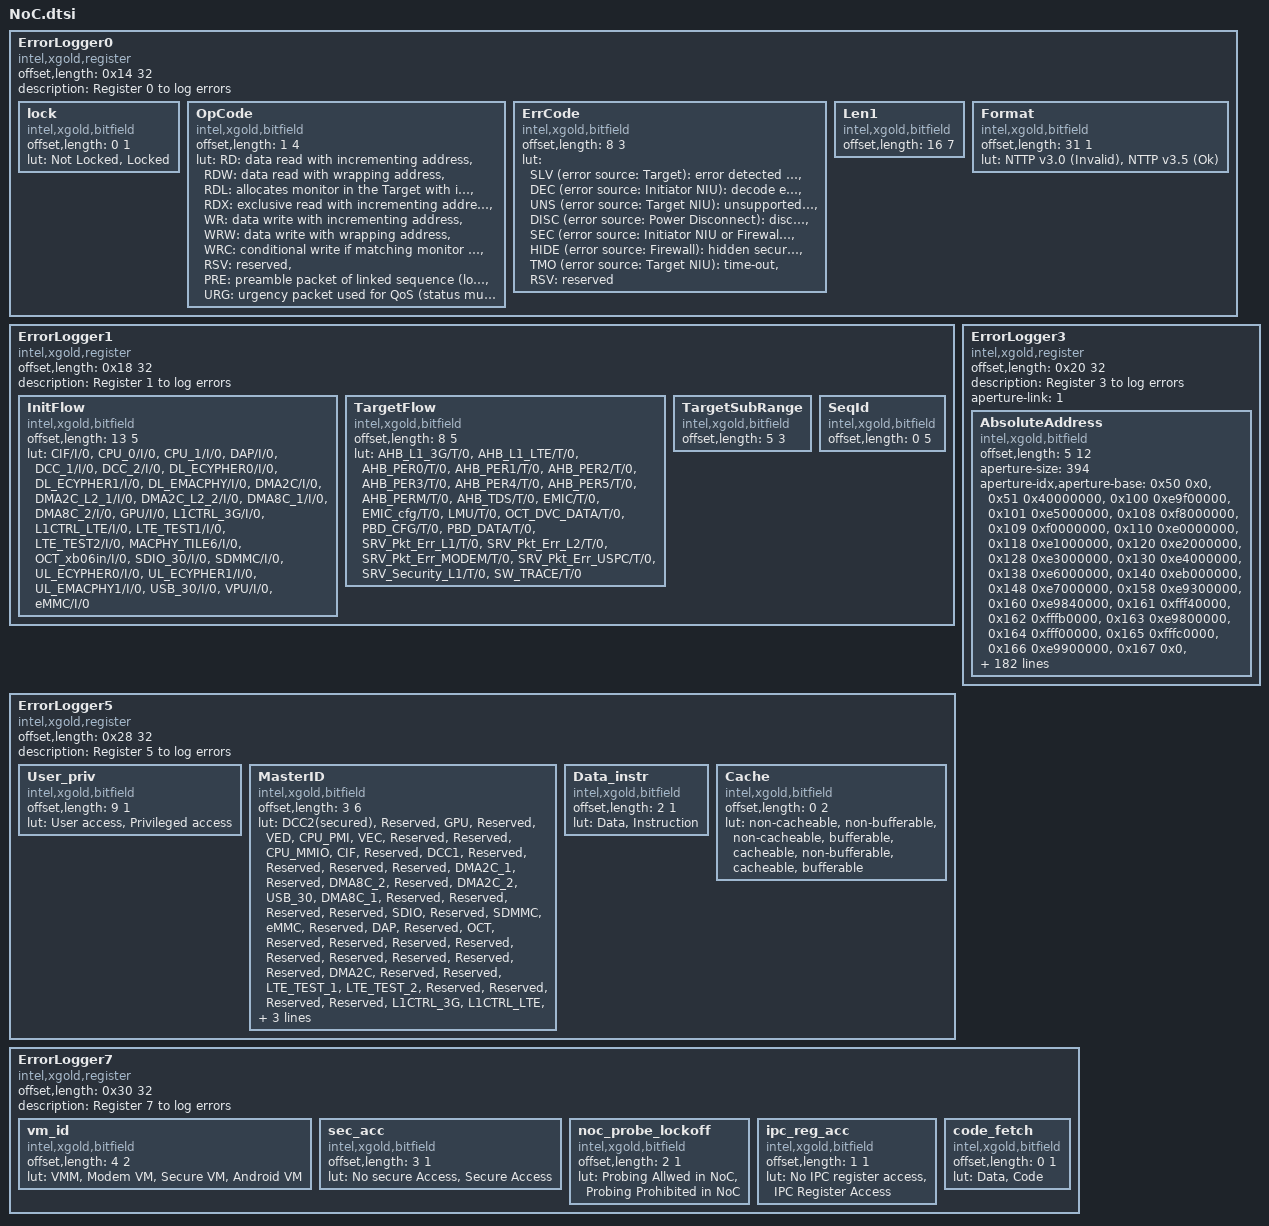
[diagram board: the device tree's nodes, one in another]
ErrorLogger0 {
	compatible = "intel,xgold,register";
	offset,length = < 0x14 32>;
	description = "Register 0 to log errors";
	lock {
		compatible = "intel,xgold,bitfield";
		offset,length = < 0 1>;
		lut = "Not Locked", "Locked";
	};
	OpCode {
		compatible = "intel,xgold,bitfield";
		offset,length = < 1 4>;
		lut = "RD: data read with incrementing address",
			"RDW: data read with wrapping address",
			"RDL: allocates monitor in the Target with incrementing address",
			"RDX: exclusive read with incrementing address",
			"WR: data write with incrementing address",
			"WRW: data write with wrapping address",
			"WRC: conditional write if matching monitor in Target is found",
			"RSV: reserved",
			"PRE: preamble packet of linked sequence (locked sequence)",
			"URG: urgency packet used for QoS (status must be REQ)";
	};
	ErrCode {
		compatible = "intel,xgold,bitfield";
		offset,length = < 8 3 >;
		lut = "SLV (error source: Target): error detected by the Slave without any information or no Error",
			"DEC (error source: Initiator NIU): decode error",
			"UNS (error source: Target NIU): unsupported access type",
			"DISC (error source: Power Disconnect): disconnected Target or NoC domain",
			"SEC (error source: Initiator NIU or Firewall): security error",
			"HIDE (error source: Firewall): hidden security error. Will be reported as OK to the initiator",
			"TMO (error source: Target NIU): time-out",
			"RSV: reserved";

	};
	Len1 {
		compatible = "intel,xgold,bitfield";
		offset,length = < 16 7 >;
	};
	Format {
		compatible = "intel,xgold,bitfield";
		offset,length = < 31 1 >;
		lut = "NTTP v3.0 (Invalid)", "NTTP v3.5 (Ok)";
	};
};

ErrorLogger1 {
	compatible = "intel,xgold,register", "intel,xgold,noc,filter,routeid";
	offset,length = < 0x18 32>;
	description = "Register 1 to log errors";
	InitFlow {
		compatible = "intel,xgold,bitfield";
		offset,length = < 13 5 >;
		lut = "CIF/I/0",
			"CPU_0/I/0",
			"CPU_1/I/0",
			"DAP/I/0",
			"DCC_1/I/0",
			"DCC_2/I/0",
			"DL_ECYPHER0/I/0",
			"DL_ECYPHER1/I/0",
			"DL_EMACPHY/I/0",
			"DMA2C/I/0",
			"DMA2C_L2_1/I/0",
			"DMA2C_L2_2/I/0",
			"DMA8C_1/I/0",
			"DMA8C_2/I/0",
			"GPU/I/0",
			"L1CTRL_3G/I/0",
			"L1CTRL_LTE/I/0",
			"LTE_TEST1/I/0",
			"LTE_TEST2/I/0",
			"MACPHY_TILE6/I/0",
			"OCT_xb06in/I/0",
			"SDIO_30/I/0",
			"SDMMC/I/0",
			"UL_ECYPHER0/I/0",
			"UL_ECYPHER1/I/0",
			"UL_EMACPHY1/I/0",
			"USB_30/I/0",
			"VPU/I/0",
			"eMMC/I/0";
	};

	TargetFlow {
		compatible = "intel,xgold,bitfield";
		offset,length = < 8 5 >;
		lut =   "AHB_L1_3G/T/0",
			"AHB_L1_LTE/T/0",
			"AHB_PER0/T/0",
			"AHB_PER1/T/0",
			"AHB_PER2/T/0",
			"AHB_PER3/T/0",
			"AHB_PER4/T/0",
			"AHB_PER5/T/0",
			"AHB_PERM/T/0",
			"AHB_TDS/T/0",
			"EMIC/T/0",
			"EMIC_cfg/T/0",
			"LMU/T/0",
			"OCT_DVC_DATA/T/0",
			"PBD_CFG/T/0",
			"PBD_DATA/T/0",
			"SRV_Pkt_Err_L1/T/0",
			"SRV_Pkt_Err_L2/T/0",
			"SRV_Pkt_Err_MODEM/T/0",
			"SRV_Pkt_Err_USPC/T/0",
			"SRV_Security_L1/T/0",
			"SW_TRACE/T/0";
	};

	TargetSubRange {
		compatible = "intel,xgold,bitfield";
		offset,length = < 5 3 >;
	};

	SeqId {
		compatible = "intel,xgold,bitfield";
		offset,length = < 0 5 >;
	};
};

ErrorLogger3 {
	/* This register does not really include a bitfield or its bitfield is 32 bits and it provides an offset address */
	/* To calculate the absolute address, you must use the initflow:targetflow:subrange from ErrorLogger3 register */
	/* And use it as an index in the aperture table. Then you must add the value of this register to the value given */
	/* by the table to get the absolute address. */
	compatible = "intel,xgold,register";
	offset,length = < 0x20 32>;
	description = "Register 3 to log errors";
	aperture-link = <1>; /* link to ErrorLogger1 whose information are required to calculate real absolute address */
	AbsoluteAddress {
		compatible = "intel,xgold,bitfield";
		offset,length = < 5 12 >;				/* bitfield initflow:targeflow:subrange from aperture-link register */
		aperture-size= < 394 >;					/* Number of line in the aperture table below */
		aperture-idx,aperture-base =			/* Aperture_idx is concatenation of initflow:targetflow:subrange bitfield from ErrorLogger1 */
    <0x50  0x0>,
    <0x51  0x40000000>,
    <0x100 0xe9f00000>,
    <0x101 0xe5000000>,
    <0x108 0xf8000000>,
    <0x109 0xf0000000>,
    <0x110 0xe0000000>,
    <0x118 0xe1000000>,
    <0x120 0xe2000000>,
    <0x128 0xe3000000>,
    <0x130 0xe4000000>,
    <0x138 0xe6000000>,
    <0x140 0xeb000000>,
    <0x148 0xe7000000>,
    <0x158 0xe9300000>,
    <0x160 0xe9840000>,
    <0x161 0xfff40000>,
    <0x162 0xfffb0000>,
    <0x163 0xe9800000>,
    <0x164 0xfff00000>,
    <0x165 0xfffc0000>,
    <0x166 0xe9900000>,
    <0x167 0x0>,
    <0x170 0xe9400000>,
    <0x178 0xe9480000>,
    <0x180 0xe9010000>,
    <0x181 0xe9013600>,
    <0x182 0xe9013400>,
    <0x183 0xe9013000>,
    <0x184 0xe9012000>,
    <0x188 0xe9014000>,
    <0x189 0xe9017400>,
    <0x18a 0xe9017000>,
    <0x18b 0xe9016000>,
    <0x190 0xe9018000>,
    <0x191 0xe901ac00>,
    <0x192 0xe901a800>,
    <0x193 0xe901a000>,
    <0x198 0xe901c000>,
    <0x199 0xe901e400>,
    <0x19a 0xe901e000>,
    <0x1a0 0xe9000000>,
    <0x1a1 0xe9002000>,
    <0x1a8 0x80000000>,
    <0x250 0x0>,
    <0x251 0x40000000>,
    <0x260 0xe9840000>,
    <0x261 0xfff40000>,
    <0x262 0xfffb0000>,
    <0x263 0xe9800000>,
    <0x264 0xfff00000>,
    <0x265 0xfffc0000>,
    <0x266 0xe9900000>,
    <0x267 0x0>,
    <0x300 0xe9f00000>,
    <0x301 0xe5000000>,
    <0x308 0xf8000000>,
    <0x309 0xf0000000>,
    <0x310 0xe0000000>,
    <0x318 0xe1000000>,
    <0x320 0xe2000000>,
    <0x328 0xe3000000>,
    <0x330 0xe4000000>,
    <0x338 0xe6000000>,
    <0x340 0xeb000000>,
    <0x348 0xe7000000>,
    <0x350 0x0>,
    <0x351 0x40000000>,
    <0x358 0xe9300000>,
    <0x360 0xe9840000>,
    <0x361 0xfff40000>,
    <0x362 0xfffb0000>,
    <0x363 0xe9800000>,
    <0x364 0xfff00000>,
    <0x365 0xfffc0000>,
    <0x366 0xe9900000>,
    <0x370 0xe9400000>,
    <0x378 0xe9480000>,
    <0x380 0xe9010000>,
    <0x381 0xe9013600>,
    <0x382 0xe9013400>,
    <0x383 0xe9013000>,
    <0x384 0xe9012000>,
    <0x388 0xe9014000>,
    <0x389 0xe9017400>,
    <0x38a 0xe9017000>,
    <0x38b 0xe9016000>,
    <0x390 0xe9018000>,
    <0x391 0xe901ac00>,
    <0x392 0xe901a800>,
    <0x393 0xe901a000>,
    <0x398 0xe901c000>,
    <0x399 0xe901e400>,
    <0x39a 0xe901e000>,
    <0x39b 0x0>,
    <0x3a0 0xe9000000>,
    <0x3a1 0xe9002000>,
    <0x450 0x0>,
    <0x451 0x40000000>,
    <0x452 0x0>,
    <0x550 0x0>,
    <0x551 0x40000000>,
    <0x552 0x0>,
    <0x600 0xe9f00000>,
    <0x601 0xe5000000>,
    <0x608 0xf8000000>,
    <0x609 0xf0000000>,
    <0x650 0x0>,
    <0x651 0x40000000>,
    <0x660 0xe9840000>,
    <0x661 0xfff40000>,
    <0x662 0xfffb0000>,
    <0x663 0xe9800000>,
    <0x664 0xfff00000>,
    <0x665 0xfffc0000>,
    <0x666 0xe9900000>,
    <0x670 0xe9400000>,
    <0x671 0x0>,
    <0x678 0xe9480000>,
    <0x700 0xe9f00000>,
    <0x701 0xe5000000>,
    <0x708 0xf8000000>,
    <0x709 0xf0000000>,
    <0x750 0x0>,
    <0x751 0x40000000>,
    <0x760 0xe9840000>,
    <0x761 0xfff40000>,
    <0x762 0xfffb0000>,
    <0x763 0xe9800000>,
    <0x764 0xfff00000>,
    <0x765 0xfffc0000>,
    <0x766 0xe9900000>,
    <0x770 0xe9400000>,
    <0x771 0x0>,
    <0x778 0xe9480000>,
    <0x800 0xe9f00000>,
    <0x801 0xe5000000>,
    <0x808 0xf8000000>,
    <0x809 0xf0000000>,
    <0x850 0x0>,
    <0x851 0x40000000>,
    <0x860 0xe9840000>,
    <0x861 0xfff40000>,
    <0x862 0xfffb0000>,
    <0x863 0xe9800000>,
    <0x864 0xfff00000>,
    <0x865 0xfffc0000>,
    <0x866 0xe9900000>,
    <0x870 0xe9400000>,
    <0x871 0x0>,
    <0x878 0xe9480000>,
    <0x918 0xe1000000>,
    <0x928 0xe3000000>,
    <0x938 0xe6000000>,
    <0x939 0x0>,
    <0x950 0x0>,
    <0x951 0x40000000>,
    <0x960 0xe9840000>,
    <0x961 0xfff40000>,
    <0x962 0xfffb0000>,
    <0x963 0xe9800000>,
    <0x964 0xfff00000>,
    <0x965 0xfffc0000>,
    <0x966 0xe9900000>,
    <0xa50 0x0>,
    <0xa51 0x40000000>,
    <0xa60 0xe9840000>,
    <0xa61 0xfff40000>,
    <0xa62 0xfffb0000>,
    <0xa63 0xe9800000>,
    <0xa64 0xfff00000>,
    <0xa65 0xfffc0000>,
    <0xa66 0xe9900000>,
    <0xa67 0x0>,
    <0xa78 0xe9480000>,
    <0xb50 0x0>,
    <0xb51 0x40000000>,
    <0xb60 0xe9840000>,
    <0xb61 0xfff40000>,
    <0xb62 0xfffb0000>,
    <0xb63 0xe9800000>,
    <0xb64 0xfff00000>,
    <0xb65 0xfffc0000>,
    <0xb66 0xe9900000>,
    <0xb67 0x0>,
    <0xb78 0xe9480000>,
    <0xc00 0xe9f00000>,
    <0xc01 0xe5000000>,
    <0xc08 0xf8000000>,
    <0xc09 0xf0000000>,
    <0xc18 0xe1000000>,
    <0xc20 0xe2000000>,
    <0xc28 0xe3000000>,
    <0xc38 0xe6000000>,
    <0xc40 0xeb000000>,
    <0xc50 0x0>,
    <0xc51 0x40000000>,
    <0xc60 0xe9840000>,
    <0xc61 0xfff40000>,
    <0xc62 0xfffb0000>,
    <0xc63 0xe9800000>,
    <0xc64 0xfff00000>,
    <0xc65 0xfffc0000>,
    <0xc66 0xe9900000>,
    <0xc67 0x0>,
    <0xd00 0xe9f00000>,
    <0xd01 0xe5000000>,
    <0xd08 0xf8000000>,
    <0xd09 0xf0000000>,
    <0xd18 0xe1000000>,
    <0xd20 0xe2000000>,
    <0xd28 0xe3000000>,
    <0xd38 0xe6000000>,
    <0xd40 0xeb000000>,
    <0xd50 0x0>,
    <0xd51 0x40000000>,
    <0xd60 0xe9840000>,
    <0xd61 0xfff40000>,
    <0xd62 0xfffb0000>,
    <0xd63 0xe9800000>,
    <0xd64 0xfff00000>,
    <0xd65 0xfffc0000>,
    <0xd66 0xe9900000>,
    <0xd67 0x0>,
    <0xe50 0x0>,
    <0xe51 0x40000000>,
    <0xe52 0x0>,
    <0xf00 0xe9f00000>,
    <0xf01 0xe5000000>,
    <0xf60 0xe9840000>,
    <0xf61 0xfff40000>,
    <0xf62 0xfffb0000>,
    <0xf63 0xe9800000>,
    <0xf64 0xfff00000>,
    <0xf65 0xfffc0000>,
    <0xf66 0xe9900000>,
    <0xf70 0xe9400000>,
    <0xf71 0x0>,
    <0xf78 0xe9480000>,
    <0x100 0xe9f00000>,
    <0x100 0xe5000000>,
    <0x103 0xe4000000>,
    <0x106 0xe9840000>,
    <0x106 0xfff40000>,
    <0x106 0xfffb0000>,
    <0x106 0xe9800000>,
    <0x106 0xfff00000>,
    <0x106 0xfffc0000>,
    <0x106 0xe9900000>,
    <0x107 0xe9400000>,
    <0x107 0x0>,
    <0x107 0xe9480000>,
    <0x115 0x0>,
    <0x115 0x40000000>,
    <0x116 0xe9840000>,
    <0x116 0xfff40000>,
    <0x116 0xfffb0000>,
    <0x116 0xe9800000>,
    <0x116 0xfff00000>,
    <0x116 0xfffc0000>,
    <0x116 0xe9900000>,
    <0x117 0xe9480000>,
    <0x117 0x0>,
    <0x125 0x0>,
    <0x125 0x40000000>,
    <0x126 0xe9840000>,
    <0x126 0xfff40000>,
    <0x126 0xfffb0000>,
    <0x126 0xe9800000>,
    <0x126 0xfff00000>,
    <0x126 0xfffc0000>,
    <0x126 0xe9900000>,
    <0x127 0xe9480000>,
    <0x127 0x0>,
    <0x130 0xe9f00000>,
    <0x130 0xe5000000>,
    <0x130 0xf8000000>,
    <0x130 0xf0000000>,
    <0x135 0x0>,
    <0x135 0x40000000>,
    <0x136 0xe9840000>,
    <0x136 0xfff40000>,
    <0x136 0xfffb0000>,
    <0x136 0xe9800000>,
    <0x136 0xfff00000>,
    <0x136 0xfffc0000>,
    <0x136 0xe9900000>,
    <0x137 0xe9400000>,
    <0x137 0x0>,
    <0x137 0xe9480000>,
    <0x145 0x0>,
    <0x145 0x40000000>,
    <0x146 0xe9840000>,
    <0x146 0xfff40000>,
    <0x146 0xfffb0000>,
    <0x146 0xe9800000>,
    <0x146 0xfff00000>,
    <0x146 0xfffc0000>,
    <0x146 0xe9900000>,
    <0x146 0x0>,
    <0x155 0x0>,
    <0x155 0x40000000>,
    <0x156 0xe9840000>,
    <0x156 0xfff40000>,
    <0x156 0xfffb0000>,
    <0x156 0xe9800000>,
    <0x156 0xfff00000>,
    <0x156 0xfffc0000>,
    <0x156 0xe9900000>,
    <0x156 0x0>,
    <0x157 0xe9480000>,
    <0x165 0x0>,
    <0x165 0x40000000>,
    <0x166 0xe9840000>,
    <0x166 0xfff40000>,
    <0x166 0xfffb0000>,
    <0x166 0xe9800000>,
    <0x166 0xfff00000>,
    <0x166 0xfffc0000>,
    <0x166 0xe9900000>,
    <0x166 0x0>,
    <0x170 0xe9f00000>,
    <0x170 0xe5000000>,
    <0x170 0xf8000000>,
    <0x170 0xf0000000>,
    <0x175 0x0>,
    <0x175 0x40000000>,
    <0x176 0xe9840000>,
    <0x176 0xfff40000>,
    <0x176 0xfffb0000>,
    <0x176 0xe9800000>,
    <0x176 0xfff00000>,
    <0x176 0xfffc0000>,
    <0x176 0xe9900000>,
    <0x177 0xe9400000>,
    <0x177 0x0>,
    <0x177 0xe9480000>,
    <0x180 0xe9f00000>,
    <0x180 0xe5000000>,
    <0x180 0xf8000000>,
    <0x180 0xf0000000>,
    <0x185 0x0>,
    <0x185 0x40000000>,
    <0x186 0xe9840000>,
    <0x186 0xfff40000>,
    <0x186 0xfffb0000>,
    <0x186 0xe9800000>,
    <0x186 0xfff00000>,
    <0x186 0xfffc0000>,
    <0x186 0xe9900000>,
    <0x187 0xe9400000>,
    <0x187 0x0>,
    <0x187 0xe9480000>,
    <0x190 0xe9f00000>,
    <0x190 0xe5000000>,
    <0x190 0xf8000000>,
    <0x190 0xf0000000>,
    <0x195 0x0>,
    <0x195 0x40000000>,
    <0x196 0xe9840000>,
    <0x196 0xfff40000>,
    <0x196 0xfffb0000>,
    <0x196 0xe9800000>,
    <0x196 0xfff00000>,
    <0x196 0xfffc0000>,
    <0x196 0xe9900000>,
    <0x197 0xe9400000>,
    <0x197 0x0>,
    <0x197 0xe9480000>,
    <0x1a5 0x0>,
    <0x1a5 0x40000000>,
    <0x1a6 0xe9840000>,
    <0x1a6 0xfff40000>,
    <0x1a6 0xfffb0000>,
    <0x1a6 0xe9800000>,
    <0x1a6 0xfff00000>,
    <0x1a6 0xfffc0000>,
    <0x1a6 0xe9900000>,
    <0x1a6 0x0>,
    <0x1a6 0xe9100000>,
    <0x1a7 0xe9480000>,
    <0x1b5 0x0>,
    <0x1b5 0x40000000>,
    <0x1b5 0x0>,
    <0x1c5 0x0>,
    <0x1c5 0x40000000>,
    <0x1c6 0xe9840000>,
    <0x1c6 0xfff40000>,
    <0x1c6 0xfffb0000>,
    <0x1c6 0xe9800000>,
    <0x1c6 0xfff00000>,
    <0x1c6 0xfffc0000>,
    <0x1c6 0xe9900000>,
    <0x1c6 0x0>;
	};
};

ErrorLogger5 {
	compatible = "intel,xgold,register";
	offset,length = < 0x28 32>;
	description = "Register 5 to log errors";

	User_priv {
		compatible = "intel,xgold,bitfield";
		offset,length = < 9 1>;
		lut = "User access", "Privileged access";
	};

	MasterID {
		compatible = "intel,xgold,bitfield";
		offset,length = < 3 6>;
		lut = 	"DCC2(secured)",
			"Reserved",
			"GPU",
			"Reserved",
			"VED",
			"CPU_PMI",
			"VEC",
			"Reserved",
			"Reserved",
			"CPU_MMIO",
			"CIF",
			"Reserved",
			"DCC1",
			"Reserved",
			"Reserved",
			"Reserved",
			"Reserved",	/* 0x10 */
			"DMA2C_1",
			"Reserved",
			"DMA8C_2",
			"Reserved",
			"DMA2C_2",
			"USB_30",
			"DMA8C_1",
			"Reserved",
			"Reserved",
			"Reserved",
			"Reserved",
			"SDIO",
			"Reserved",
			"SDMMC",
			"eMMC",
			"Reserved",	/* 0x20 */
			"DAP",
			"Reserved",
			"OCT",
			"Reserved",
			"Reserved",
			"Reserved",
			"Reserved",
			"Reserved",
			"Reserved",
			"Reserved",
			"Reserved",
			"Reserved",
			"DMA2C",
			"Reserved",
			"Reserved",
			"LTE_TEST_1",	/* 0x30 */
			"LTE_TEST_2",
			"Reserved",
			"Reserved",
			"Reserved",
			"Reserved",
			"L1CTRL_3G",
			"L1CTRL_LTE",
			"MACPHY_TILE0",
			"MACPHY_TILE2",
			"MACPHY_TILE1",
			"MACPHY_TILE6",
			"MACPHY_TILE3",
			"Reserved",
			"MACPHY_TILE4",
			"MACPHY_TILE5";
	};

	Data_instr {
		compatible = "intel,xgold,bitfield";
		offset,length = < 2 1>;
		lut = "Data", "Instruction";
	};

	Cache {
		compatible = "intel,xgold,bitfield";
		offset,length = < 0 2>;
		lut = "non-cacheable, non-bufferable",
			"non-cacheable, bufferable",
			"cacheable, non-bufferable",
			"cacheable, bufferable";
	};
};

ErrorLogger7 {
	compatible = "intel,xgold,register", "intel,xgold,noc,filter,security";
	offset,length = < 0x30 32>;
	description = "Register 7 to log errors";
	vm_id {
		compatible = "intel,xgold,bitfield";
		offset,length = < 4 2>;
		lut = "VMM", "Modem VM", "Secure VM", "Android VM";
	};

	sec_acc {
		compatible = "intel,xgold,bitfield";
		offset,length = < 3 1>;
		lut = "No secure Access", "Secure Access";
	};

	noc_probe_lockoff {
		compatible = "intel,xgold,bitfield";
		offset,length = < 2 1>;
		lut = "Probing Allwed in NoC", "Probing Prohibited in NoC";
	};

	ipc_reg_acc {
		compatible = "intel,xgold,bitfield";
		offset,length = < 1 1>;
		lut = "No IPC register access", "IPC Register Access";
	};

	code_fetch {
		compatible = "intel,xgold,bitfield";
		offset,length = < 0 1>;
		lut = "Data", "Code";
	};

};
